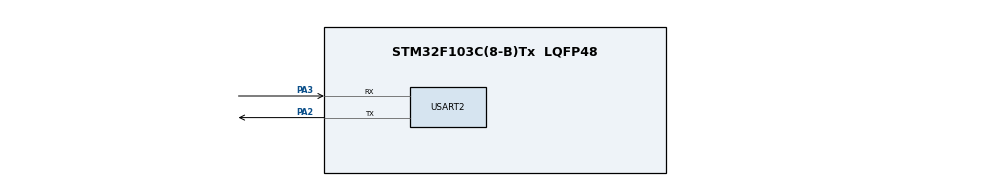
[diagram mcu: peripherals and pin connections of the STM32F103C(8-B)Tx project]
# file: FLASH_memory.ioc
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Mcu.Family=STM32F1
Mcu.Name=STM32F103C(8-B)Tx
Mcu.Package=LQFP48
NVIC.PriorityGroup=NVIC_PRIORITYGROUP_4
PA13.Mode=Serial_Wire
PA13.Signal=SYS_JTMS-SWDIO
PA14.Mode=Serial_Wire
PA14.Signal=SYS_JTCK-SWCLK
PA2.Mode=Asynchronous
PA2.Signal=USART2_TX
PA3.Mode=Asynchronous
PA3.Signal=USART2_RX
PD0-OSC_IN.Mode=HSE-External-Oscillator
PD0-OSC_IN.Signal=RCC_OSC_IN
PD1-OSC_OUT.Mode=HSE-External-Oscillator
PD1-OSC_OUT.Signal=RCC_OSC_OUT
ProjectManager.HeapSize=0x200
ProjectManager.StackSize=0x400
ProjectManager.TargetToolchain=MDK-ARM V5.32
RCC.APB1Freq_Value=8000000
RCC.APB2Freq_Value=8000000
RCC.SYSCLKSource=RCC_SYSCLKSOURCE_PLLCLK
USART2.VirtualMode=VM_ASYNC
board=custom

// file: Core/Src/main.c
/* USER CODE BEGIN Header */
/**
  ******************************************************************************
  * @file           : main.c
  * @brief          : Main program body
  ******************************************************************************
  * @attention
  *
  * Copyright (c) 2025 STMicroelectronics.
  * All rights reserved.
  *
  * This software is licensed under terms that can be found in the LICENSE file
  * in the root directory of this software component.
  * If no LICENSE file comes with this software, it is provided AS-IS.
  *
  ******************************************************************************
  */
/* USER CODE END Header */
#include "main.h"

/* USER CODE BEGIN Includes */
#include <stdio.h>
/* USER CODE END Includes */

UART_HandleTypeDef huart2;

void SystemClock_Config(void);
static void MX_GPIO_Init(void);
static void MX_USART2_UART_Init(void);

/* USER CODE BEGIN 0 */
uint32_t write_data[4] = {0x12345678,0x02020202,0x87654321,0x04040404};
uint32_t read_data[4];

typedef enum
{
	DATA_TYPE_16 = 0,
	DATA_TYPE_32 = 1,
}DataTypeDef;

void flash_write_data(uint32_t page_addr, uint32_t offset_addr, void* data, uint16_t size, DataTypeDef data_type_def)
{
	HAL_FLASH_Unlock();

	FLASH_EraseInitTypeDef pEraseinit;
	pEraseinit.TypeErase = FLASH_TYPEERASE_PAGES;
	pEraseinit.PageAddress = page_addr;
	pEraseinit.NbPages = 1;

	uint32_t page_err;

	HAL_FLASHEx_Erase(&pEraseinit, &page_err);

	uint32_t temp_addr = offset_addr + page_addr;
	if(data_type_def == DATA_TYPE_16){
		for(int i=0; i<size; i++)
		{
			HAL_FLASH_Program(FLASH_TYPEPROGRAM_HALFWORD, temp_addr, ((uint16_t*)data)[i]);
			temp_addr+=2;
		}
	}else if(data_type_def == DATA_TYPE_32){
		for(int i=0; i<size; i++)
		{
			HAL_FLASH_Program(FLASH_TYPEPROGRAM_WORD, temp_addr, ((uint32_t*)data)[i]);
			temp_addr+=4;
		}
	}
	HAL_FLASH_Lock();
}

void flash_read_data(uint32_t page_addr, uint32_t offset_addr, void* data, uint16_t size, DataTypeDef data_type_def)
{
	uint32_t temp_addr = page_addr + offset_addr;

	if(data_type_def == DATA_TYPE_16){
		for(int i=0;i<size;i++)
		{
			*((uint16_t*)data+i) = *((uint16_t*)temp_addr);
			temp_addr+=2;
		}
	}else if(data_type_def == DATA_TYPE_32){
		for(int i=0;i<size;i++)
		{
			*((uint32_t*)data+i) = *((uint32_t*)temp_addr);
			temp_addr+=4;
		}
	}
}
/* USER CODE END 0 */

int main(void)
{

  /* MCU Configuration--------------------------------------------------------*/

  /* Reset of all peripherals, Initializes the Flash interface and the Systick. */
  HAL_Init();

  /* Configure the system clock */
  SystemClock_Config();

  /* Initialize all configured peripherals */
  MX_GPIO_Init();
  MX_USART2_UART_Init();
  /* USER CODE BEGIN 2 */
	uint32_t page_addr = 0x08007C00;
	DataTypeDef type_def = DATA_TYPE_32;
	flash_write_data(page_addr, 0, write_data, 4, type_def);
	flash_read_data(page_addr, 0, read_data, 4, type_def);
  /* USER CODE END 2 */

  /* Infinite loop */
  /* USER CODE BEGIN WHILE */
  while (1)
  {
		printf("data1 = %x\r\n",read_data[0]);
		printf("data2 = %x\r\n",read_data[1]);
		printf("data3 = %x\r\n",read_data[2]);
		printf("data4 = %x\r\n",read_data[3]);
		HAL_Delay(1000);
    /* USER CODE END WHILE */

  }
}

void SystemClock_Config(void)
{
  RCC_OscInitTypeDef RCC_OscInitStruct = {0};
  RCC_ClkInitTypeDef RCC_ClkInitStruct = {0};

  /** Initializes the RCC Oscillators according to the specified parameters
  * in the RCC_OscInitTypeDef structure.
  */
  RCC_OscInitStruct.OscillatorType = RCC_OSCILLATORTYPE_HSI;
  RCC_OscInitStruct.HSIState = RCC_HSI_ON;
  RCC_OscInitStruct.HSICalibrationValue = RCC_HSICALIBRATION_DEFAULT;
  RCC_OscInitStruct.PLL.PLLState = RCC_PLL_ON;
  RCC_OscInitStruct.PLL.PLLSource = RCC_PLLSOURCE_HSI_DIV2;
  RCC_OscInitStruct.PLL.PLLMUL = RCC_PLL_MUL2;
  if (HAL_RCC_OscConfig(&RCC_OscInitStruct) != HAL_OK)
  {
    Error_Handler();
  }

  /** Initializes the CPU, AHB and APB buses clocks
  */
  RCC_ClkInitStruct.ClockType = RCC_CLOCKTYPE_HCLK|RCC_CLOCKTYPE_SYSCLK
                              |RCC_CLOCKTYPE_PCLK1|RCC_CLOCKTYPE_PCLK2;
  RCC_ClkInitStruct.SYSCLKSource = RCC_SYSCLKSOURCE_PLLCLK;
  RCC_ClkInitStruct.AHBCLKDivider = RCC_SYSCLK_DIV1;
  RCC_ClkInitStruct.APB1CLKDivider = RCC_HCLK_DIV1;
  RCC_ClkInitStruct.APB2CLKDivider = RCC_HCLK_DIV1;

  if (HAL_RCC_ClockConfig(&RCC_ClkInitStruct, FLASH_LATENCY_0) != HAL_OK)
  {
    Error_Handler();
  }
}

static void MX_USART2_UART_Init(void)
{

  huart2.Instance = USART2;
  huart2.Init.BaudRate = 115200;
  huart2.Init.WordLength = UART_WORDLENGTH_8B;
  huart2.Init.StopBits = UART_STOPBITS_1;
  huart2.Init.Parity = UART_PARITY_NONE;
  huart2.Init.Mode = UART_MODE_TX_RX;
  huart2.Init.HwFlowCtl = UART_HWCONTROL_NONE;
  huart2.Init.OverSampling = UART_OVERSAMPLING_16;
  if (HAL_UART_Init(&huart2) != HAL_OK)
  {
    Error_Handler();
  }

}

static void MX_GPIO_Init(void)
{

  /* GPIO Ports Clock Enable */
  __HAL_RCC_GPIOD_CLK_ENABLE();
  __HAL_RCC_GPIOA_CLK_ENABLE();

}

/* USER CODE BEGIN 4 */
struct __FILE{
  int handle;
  /* Whatever you require here. If the only file you are using is */
  /* standard output using printf() for debugging, no file handling */
  /* is required. */
};
FILE __stdout;

int fputc(int ch, FILE *f){
	HAL_UART_Transmit(&huart2, (uint8_t *)&ch, 1, 0xFFFF);
  return ch;
}

int ferror(FILE *f){
  /* Your implementation of ferror(). */
  return 0;
}
/* USER CODE END 4 */

void Error_Handler(void)
{
  __disable_irq();
  while (1)
  {
  }
}
